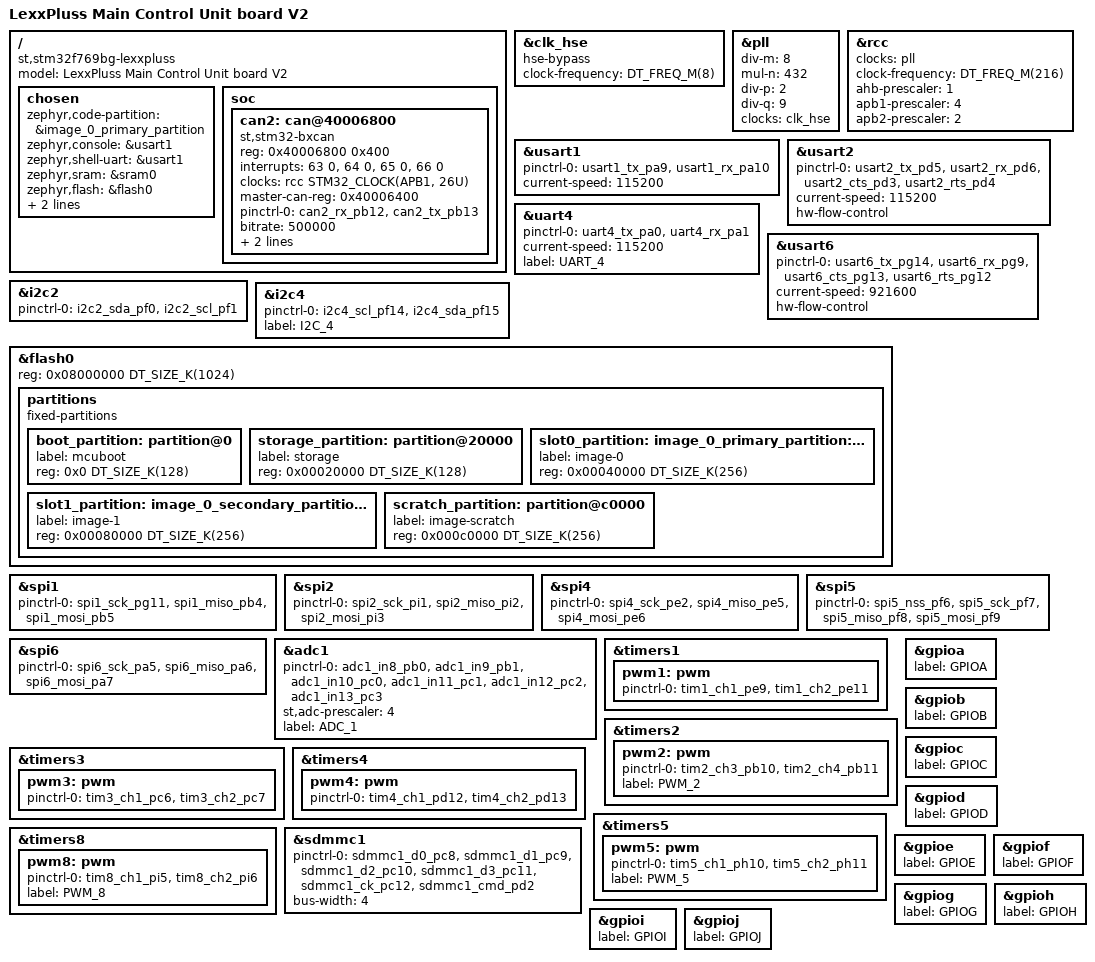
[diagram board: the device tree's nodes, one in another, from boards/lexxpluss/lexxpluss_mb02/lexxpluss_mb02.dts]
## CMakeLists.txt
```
# SPDX-License-Identifier: BSD-2-Clause
cmake_minimum_required(VERSION 3.20.0)
list(APPEND BOARD_ROOT ${CMAKE_CURRENT_LIST_DIR})
find_package(Zephyr REQUIRED HINTS $ENV{ZEPHYR_BASE})
project(spike_minimal)
target_sources(app PRIVATE src/main.c)
```

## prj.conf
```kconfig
CONFIG_SERIAL=y
CONFIG_CONSOLE=y
CONFIG_UART_CONSOLE=y
CONFIG_PRINTK=y
CONFIG_GPIO=y
```

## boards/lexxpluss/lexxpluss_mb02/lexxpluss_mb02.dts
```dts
/dts-v1/;
#include <mem.h>
#include <st/f7/stm32f769Xi.dtsi>
#include <st/f7/stm32f769b(g-i)tx-pinctrl.dtsi>

/ {
	model = "LexxPluss Main Control Unit board V2";
	compatible = "st,stm32f769bg-lexxpluss";

	chosen {
		zephyr,code-partition = &image_0_primary_partition;
		zephyr,console = &usart1;
		zephyr,shell-uart = &usart1;
		zephyr,sram = &sram0;
		zephyr,flash = &flash0;
		zephyr,dtcm = &dtcm;
		zephyr,canbus = &can2;
	};

	soc {
		/* upstream F7 dtsi defines only can1; CAN2 is the bxCAN slave of CAN1 */
		can2: can@40006800 {
			compatible = "st,stm32-bxcan";
			reg = <0x40006800 0x400>;
			interrupts = <63 0>, <64 0>, <65 0>, <66 0>;
			interrupt-names = "TX", "RX0", "RX1", "SCE";
			clocks = <&rcc STM32_CLOCK(APB1, 26U)>;
			master-can-reg = <0x40006400>;
			status = "disabled";
		};
	};
};

&clk_hse {
	hse-bypass;
	clock-frequency = <DT_FREQ_M(8)>;
	status = "okay";
};

&pll {
	div-m = <8>;
	mul-n = <432>;
	div-p = <2>;
	div-q = <9>;
	clocks = <&clk_hse>;
	status = "okay";
};

&rcc {
	clocks = <&pll>;
	clock-frequency = <DT_FREQ_M(216)>;
	ahb-prescaler = <1>;
	apb1-prescaler = <4>;
	apb2-prescaler = <2>;
};

&usart1 {
	pinctrl-0 = <&usart1_tx_pa9 &usart1_rx_pa10>;
	pinctrl-names = "default";
	current-speed = <115200>;
	status = "okay";
};

&usart2 {
	pinctrl-0 = <&usart2_tx_pd5 &usart2_rx_pd6 &usart2_cts_pd3 &usart2_rts_pd4>;
	pinctrl-names = "default";
	current-speed = <115200>;
	hw-flow-control;
	status = "okay";
};

&uart4 {
	pinctrl-0 = <&uart4_tx_pa0 &uart4_rx_pa1>;
	pinctrl-names = "default";
	current-speed = <115200>;
	status = "okay";
};

&usart6 {
	pinctrl-0 = <&usart6_tx_pg14 &usart6_rx_pg9 &usart6_cts_pg13 &usart6_rts_pg12>;
	pinctrl-names = "default";
	current-speed = <921600>;
	hw-flow-control;
	status = "okay";
};

&can2 {
	pinctrl-0 = <&can2_rx_pb12 &can2_tx_pb13>;
	pinctrl-names = "default";
	bitrate = <500000>;
	/* 2.6 timing prop-seg 0, phase-seg1 5, phase-seg2 6 (12 TQ) = sample point 6/12 */
	sample-point = <500>;
	status = "okay";
};

&i2c2 {
	pinctrl-0 = <&i2c2_sda_pf0 &i2c2_scl_pf1>;
	pinctrl-names = "default";
	status = "okay";
};

&i2c4 {
	pinctrl-0 = <&i2c4_scl_pf14 &i2c4_sda_pf15>;
	pinctrl-names = "default";
	status = "okay";
};

&flash0 {
	/* STM32F769BG has 1 MiB flash; the upstream dtsi describes the 2 MiB F769xI */
	reg = <0x08000000 DT_SIZE_K(1024)>;

	partitions {
		compatible = "fixed-partitions";
		#address-cells = <1>;
		#size-cells = <1>;

		boot_partition: partition@0 {
			label = "mcuboot";
			reg = <0x0 DT_SIZE_K(128)>;
		};
		storage_partition: partition@20000 {
			label = "storage";
			reg = <0x00020000 DT_SIZE_K(128)>;
		};
		slot0_partition: image_0_primary_partition: partition@40000 {
			label = "image-0";
			reg = <0x00040000 DT_SIZE_K(256)>;
		};
		slot1_partition: image_0_secondary_partition: partition@80000 {
			label = "image-1";
			reg = <0x00080000 DT_SIZE_K(256)>;
		};
		scratch_partition: partition@c0000 {
			label = "image-scratch";
			reg = <0x000c0000 DT_SIZE_K(256)>;
		};
	};
};

/* Peripherals the firmware needs; sensor and LED device nodes are added later. */

&spi1 {
	pinctrl-0 = <&spi1_sck_pg11 &spi1_miso_pb4 &spi1_mosi_pb5>;
	pinctrl-names = "default";
	status = "okay";
};

&spi2 {
	pinctrl-0 = <&spi2_sck_pi1 &spi2_miso_pi2 &spi2_mosi_pi3>;
	pinctrl-names = "default";
	status = "okay";
};

&spi4 {
	pinctrl-0 = <&spi4_sck_pe2 &spi4_miso_pe5 &spi4_mosi_pe6>;
	pinctrl-names = "default";
	status = "okay";
};

&spi5 {
	pinctrl-0 = <&spi5_nss_pf6 &spi5_sck_pf7 &spi5_miso_pf8 &spi5_mosi_pf9>;
	pinctrl-names = "default";
	status = "okay";
};

&spi6 {
	pinctrl-0 = <&spi6_sck_pa5 &spi6_miso_pa6 &spi6_mosi_pa7>;
	pinctrl-names = "default";
	status = "okay";
};

&adc1 {
	pinctrl-0 = <&adc1_in8_pb0 &adc1_in9_pb1 &adc1_in10_pc0
		     &adc1_in11_pc1 &adc1_in12_pc2 &adc1_in13_pc3>;
	pinctrl-names = "default";
	/* APB2 108 MHz / 4 = 27 MHz, below the 36 MHz F7 ADC limit */
	st,adc-prescaler = <4>;
	status = "okay";
};

&timers1 {
	status = "okay";
	pwm1: pwm {
		status = "okay";
		pinctrl-0 = <&tim1_ch1_pe9 &tim1_ch2_pe11>;
		pinctrl-names = "default";
	};
};

&timers2 {
	status = "okay";
	pwm2: pwm {
		status = "okay";
		pinctrl-0 = <&tim2_ch3_pb10 &tim2_ch4_pb11>;
		pinctrl-names = "default";
		label = "PWM_2";
	};
};

&timers3 {
	status = "okay";
	pwm3: pwm {
		status = "okay";
		pinctrl-0 = <&tim3_ch1_pc6 &tim3_ch2_pc7>;
		pinctrl-names = "default";
	};
};

&timers4 {
	status = "okay";
	pwm4: pwm {
		status = "okay";
		pinctrl-0 = <&tim4_ch1_pd12 &tim4_ch2_pd13>;
		pinctrl-names = "default";
	};
};

&timers5 {
	status = "okay";
	pwm5: pwm {
		status = "okay";
		pinctrl-0 = <&tim5_ch1_ph10 &tim5_ch2_ph11>;
		pinctrl-names = "default";
		label = "PWM_5";
	};
};

&timers8 {
	status = "okay";
	pwm8: pwm {
		status = "okay";
		pinctrl-0 = <&tim8_ch1_pi5 &tim8_ch2_pi6>;
		pinctrl-names = "default";
		label = "PWM_8";
	};
};

/* The STM32 SDMMC driver registers the disk as "SD" (disk-name default). */
&sdmmc1 {
	pinctrl-0 = <&sdmmc1_d0_pc8 &sdmmc1_d1_pc9 &sdmmc1_d2_pc10
		     &sdmmc1_d3_pc11 &sdmmc1_ck_pc12 &sdmmc1_cmd_pd2>;
	pinctrl-names = "default";
	bus-width = <4>;
	status = "okay";
};

/*
 * In Zephyr 4.x device_get_binding() matches the node "label" property (or the
 * node name when absent). The firmware looks devices up by these 2.6 names.
 */
&gpioa { label = "GPIOA"; };
&gpiob { label = "GPIOB"; };
&gpioc { label = "GPIOC"; };
&gpiod { label = "GPIOD"; };
&gpioe { label = "GPIOE"; };
&gpiof { label = "GPIOF"; };
&gpiog { label = "GPIOG"; };
&gpioh { label = "GPIOH"; };
&gpioi { label = "GPIOI"; };
&gpioj { label = "GPIOJ"; };
&uart4 { label = "UART_4"; };
&i2c4 { label = "I2C_4"; };
&can2 { label = "CAN_2"; };
&adc1 { label = "ADC_1"; };
```

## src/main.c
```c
#include <zephyr/kernel.h>

int main(void)
{
	for (;;) {
		printk("spike_minimal alive %u\n", k_uptime_get_32());
		k_sleep(K_SECONDS(1));
	}
	return 0;
}
```
